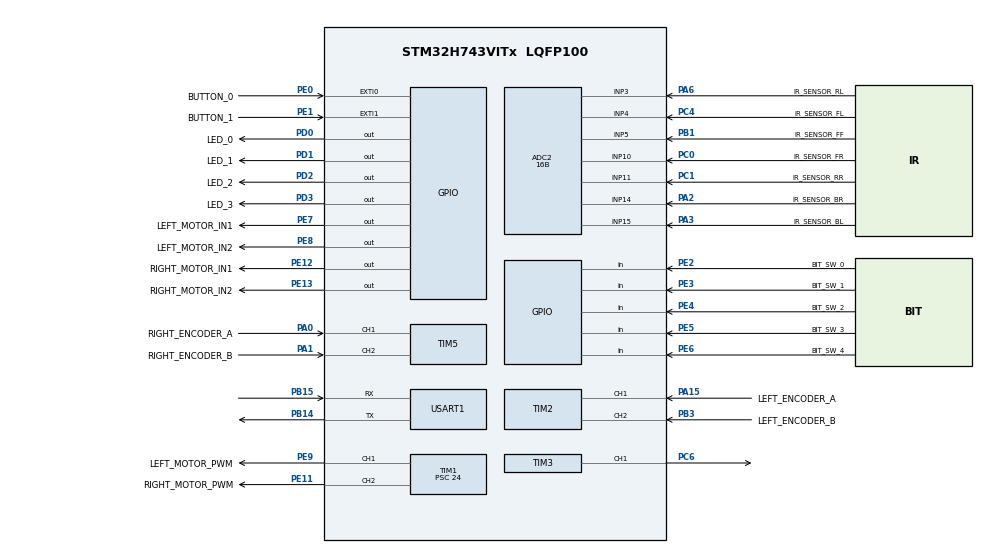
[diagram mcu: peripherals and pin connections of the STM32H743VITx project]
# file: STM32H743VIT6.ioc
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ADC2.Channel-1\#ChannelRegularConversion=ADC_CHANNEL_5
ADC2.Channel-2\#ChannelRegularConversion=ADC_CHANNEL_4
ADC2.Channel-3\#ChannelRegularConversion=ADC_CHANNEL_3
ADC2.Channel-4\#ChannelRegularConversion=ADC_CHANNEL_15
ADC2.Channel-5\#ChannelRegularConversion=ADC_CHANNEL_14
ADC2.Channel-6\#ChannelRegularConversion=ADC_CHANNEL_11
ADC2.Channel-8\#ChannelRegularConversion=ADC_CHANNEL_10
ADC2.ClockPrescaler=ADC_CLOCK_ASYNC_DIV256
ADC2.ContinuousConvMode=ENABLE
ADC2.DiscontinuousConvMode=DISABLE
ADC2.NbrOfConversion=7
ADC2.NbrOfConversionFlag=1
ADC2.OffsetNumber-1\#ChannelRegularConversion=ADC_OFFSET_NONE
ADC2.OffsetNumber-2\#ChannelRegularConversion=ADC_OFFSET_NONE
ADC2.OffsetNumber-3\#ChannelRegularConversion=ADC_OFFSET_NONE
ADC2.OffsetNumber-4\#ChannelRegularConversion=ADC_OFFSET_NONE
ADC2.OffsetNumber-5\#ChannelRegularConversion=ADC_OFFSET_NONE
ADC2.OffsetNumber-6\#ChannelRegularConversion=ADC_OFFSET_NONE
ADC2.OffsetNumber-8\#ChannelRegularConversion=ADC_OFFSET_NONE
ADC2.OffsetSignedSaturation-1\#ChannelRegularConversion=DISABLE
ADC2.OffsetSignedSaturation-2\#ChannelRegularConversion=DISABLE
ADC2.OffsetSignedSaturation-3\#ChannelRegularConversion=DISABLE
ADC2.OffsetSignedSaturation-4\#ChannelRegularConversion=DISABLE
ADC2.OffsetSignedSaturation-5\#ChannelRegularConversion=DISABLE
ADC2.OffsetSignedSaturation-6\#ChannelRegularConversion=DISABLE
ADC2.OffsetSignedSaturation-8\#ChannelRegularConversion=DISABLE
ADC2.OversamplingMode=DISABLE
ADC2.Rank-1\#ChannelRegularConversion=1
ADC2.Rank-2\#ChannelRegularConversion=2
ADC2.Rank-3\#ChannelRegularConversion=3
ADC2.Rank-4\#ChannelRegularConversion=4
ADC2.Rank-5\#ChannelRegularConversion=5
ADC2.Rank-6\#ChannelRegularConversion=6
ADC2.Rank-8\#ChannelRegularConversion=7
ADC2.Resolution=ADC_RESOLUTION_16B
ADC2.SamplingTime-1\#ChannelRegularConversion=ADC_SAMPLETIME_64CYCLES_5
ADC2.SamplingTime-2\#ChannelRegularConversion=ADC_SAMPLETIME_64CYCLES_5
ADC2.SamplingTime-3\#ChannelRegularConversion=ADC_SAMPLETIME_64CYCLES_5
ADC2.SamplingTime-4\#ChannelRegularConversion=ADC_SAMPLETIME_64CYCLES_5
ADC2.SamplingTime-5\#ChannelRegularConversion=ADC_SAMPLETIME_64CYCLES_5
ADC2.SamplingTime-6\#ChannelRegularConversion=ADC_SAMPLETIME_64CYCLES_5
ADC2.SamplingTime-8\#ChannelRegularConversion=ADC_SAMPLETIME_64CYCLES_5
CORTEX_M7.default_mode_Activation=1
Dma.Request0=USART1_RX
Dma.USART1_RX.0.Direction=DMA_PERIPH_TO_MEMORY
Dma.USART1_RX.0.EventEnable=DISABLE
Dma.USART1_RX.0.FIFOMode=DMA_FIFOMODE_DISABLE
Dma.USART1_RX.0.Instance=DMA1_Stream0
Dma.USART1_RX.0.MemDataAlignment=DMA_MDATAALIGN_BYTE
Dma.USART1_RX.0.MemInc=DMA_MINC_ENABLE
Dma.USART1_RX.0.Mode=DMA_NORMAL
Dma.USART1_RX.0.PeriphDataAlignment=DMA_PDATAALIGN_BYTE
Dma.USART1_RX.0.PeriphInc=DMA_PINC_DISABLE
Dma.USART1_RX.0.Polarity=HAL_DMAMUX_REQ_GEN_RISING
Dma.USART1_RX.0.Priority=DMA_PRIORITY_LOW
Dma.USART1_RX.0.RequestNumber=1
Dma.USART1_RX.0.SignalID=NONE
Dma.USART1_RX.0.SyncEnable=DISABLE
Dma.USART1_RX.0.SyncPolarity=HAL_DMAMUX_SYNC_NO_EVENT
Dma.USART1_RX.0.SyncRequestNumber=1
Dma.USART1_RX.0.SyncSignalID=NONE
Mcu.Family=STM32H7
Mcu.Name=STM32H743VITx
Mcu.Package=LQFP100
NVIC.ADC_IRQn=true\:0\:0\:false\:false\:true\:true\:true\:true
NVIC.DMA1_Stream0_IRQn=true\:1\:0\:true\:false\:true\:false\:true\:true
NVIC.PriorityGroup=NVIC_PRIORITYGROUP_4
NVIC.TIM7_IRQn=true\:2\:0\:true\:false\:true\:true\:true\:true
NVIC.USART1_IRQn=true\:1\:0\:true\:false\:true\:true\:true\:true
PA0.GPIO_Label=RIGHT_ENCODER_A
PA0.Signal=S_TIM5_CH1
PA1.GPIO_Label=RIGHT_ENCODER_B
PA1.Signal=S_TIM5_CH2
PA13\ (JTMS/SWDIO).Mode=Serial_Wire
PA13\ (JTMS/SWDIO).Signal=DEBUG_JTMS-SWDIO
PA14\ (JTCK/SWCLK).Mode=Serial_Wire
PA14\ (JTCK/SWCLK).Signal=DEBUG_JTCK-SWCLK
PA15\ (JTDI).GPIO_Label=LEFT_ENCODER_A
PA15\ (JTDI).Signal=S_TIM2_CH1_ETR
PA2.GPIO_Label=IR_SENSOR_BR
PA2.Signal=ADCx_INP14
PA3.GPIO_Label=IR_SENSOR_BL
PA3.Signal=ADCx_INP15
PA6.GPIO_Label=IR_SENSOR_RL
PA6.Signal=ADCx_INP3
PB1.GPIO_Label=IR_SENSOR_FF
PB1.Signal=ADCx_INP5
PB14.Mode=Asynchronous
PB14.Signal=USART1_TX
PB15.Mode=Asynchronous
PB15.Signal=USART1_RX
PB3\ (JTDO/TRACESWO).GPIO_Label=LEFT_ENCODER_B
PB3\ (JTDO/TRACESWO).Signal=S_TIM2_CH2
PC0.GPIO_Label=IR_SENSOR_FR
PC0.Signal=ADCx_INP10
PC1.GPIO_Label=IR_SENSOR_RR
PC1.Signal=ADCx_INP11
PC4.GPIO_Label=IR_SENSOR_FL
PC4.Signal=ADCx_INP4
PC6.Signal=S_TIM3_CH1
PD0.GPIO_Label=LED_0
PD0.Signal=GPIO_Output
PD1.GPIO_Label=LED_1
PD1.Signal=GPIO_Output
PD2.GPIO_Label=LED_2
PD2.Signal=GPIO_Output
PD3.GPIO_Label=LED_3
PD3.Signal=GPIO_Output
PE0.GPIO_Label=BUTTON_0
PE0.Signal=GPXTI0
PE1.GPIO_Label=BUTTON_1
PE1.Signal=GPXTI1
PE11.GPIO_Label=RIGHT_MOTOR_PWM
PE11.Signal=S_TIM1_CH2
PE12.GPIO_Label=RIGHT_MOTOR_IN1
PE12.Signal=GPIO_Output
PE13.GPIO_Label=RIGHT_MOTOR_IN2
PE13.Signal=GPIO_Output
PE2.GPIO_Label=BIT_SW_0
PE2.GPIO_PuPd=GPIO_PULLDOWN
PE2.Signal=GPIO_Input
PE3.GPIO_Label=BIT_SW_1
PE3.GPIO_PuPd=GPIO_PULLDOWN
PE3.Signal=GPIO_Input
PE4.GPIO_Label=BIT_SW_2
PE4.GPIO_PuPd=GPIO_PULLDOWN
PE4.Signal=GPIO_Input
PE5.GPIO_Label=BIT_SW_3
PE5.GPIO_PuPd=GPIO_PULLDOWN
PE5.Signal=GPIO_Input
PE6.GPIO_Label=BIT_SW_4
PE6.GPIO_PuPd=GPIO_PULLDOWN
PE6.Signal=GPIO_Input
PE7.GPIO_Label=LEFT_MOTOR_IN1
PE7.Signal=GPIO_Output
PE8.GPIO_Label=LEFT_MOTOR_IN2
PE8.Signal=GPIO_Output
PE9.GPIO_Label=LEFT_MOTOR_PWM
PE9.Signal=S_TIM1_CH1
PH0-OSC_IN\ (PH0).Mode=HSE-External-Oscillator
PH0-OSC_IN\ (PH0).Signal=RCC_OSC_IN
PH1-OSC_OUT\ (PH1).Mode=HSE-External-Oscillator
PH1-OSC_OUT\ (PH1).Signal=RCC_OSC_OUT
ProjectManager.HeapSize=0x200
ProjectManager.StackSize=0x400
ProjectManager.TargetToolchain=STM32CubeIDE
RCC.ADCFreq_Value=96750000
RCC.APB1Freq_Value=120000000
RCC.APB2Freq_Value=120000000
RCC.APB3Freq_Value=120000000
RCC.APB4Freq_Value=120000000
RCC.CortexFreq_Value=480000000
RCC.D1PPRE=RCC_APB3_DIV2
RCC.D2PPRE1=RCC_APB1_DIV2
RCC.D2PPRE2=RCC_APB2_DIV2
RCC.D3PPRE=RCC_APB4_DIV2
RCC.DIVM1=3
RCC.DIVN1=60
RCC.HCLKFreq_Value=240000000
RCC.HPRE=RCC_HCLK_DIV2
RCC.HSE_VALUE=48000000
RCC.PLLFRACN=0
RCC.PLLSourceVirtual=RCC_PLLSOURCE_HSE
RCC.SYSCLKFreq_VALUE=480000000
RCC.SYSCLKSource=RCC_SYSCLKSOURCE_PLLCLK
RCC.USBFreq_Value=480000000
SH.ADCx_INP10.0=ADC2_INP10,IN10-Single-Ended
SH.ADCx_INP11.0=ADC2_INP11,IN11-Single-Ended
SH.ADCx_INP14.0=ADC2_INP14,IN14-Single-Ended
SH.ADCx_INP15.0=ADC2_INP15,IN15-Single-Ended
SH.ADCx_INP3.0=ADC2_INP3,IN3-Single-Ended
SH.ADCx_INP4.0=ADC2_INP4,IN4-Single-Ended
SH.ADCx_INP5.0=ADC2_INP5,IN5-Single-Ended
SH.S_TIM1_CH1.0=TIM1_CH1,PWM Generation1 CH1
SH.S_TIM1_CH2.0=TIM1_CH2,PWM Generation2 CH2
SH.S_TIM2_CH1_ETR.0=TIM2_CH1,Encoder_Interface
SH.S_TIM2_CH2.0=TIM2_CH2,Encoder_Interface
SH.S_TIM3_CH1.0=TIM3_CH1,PWM Generation1 CH1
SH.S_TIM5_CH1.0=TIM5_CH1,Encoder_Interface
SH.S_TIM5_CH2.0=TIM5_CH2,Encoder_Interface
TIM1.Channel-PWM\ Generation1\ CH1=TIM_CHANNEL_1
TIM1.Channel-PWM\ Generation2\ CH2=TIM_CHANNEL_2
TIM1.Period=999
TIM1.Prescaler=24
TIM2.ClockDivision=TIM_CLOCKDIVISION_DIV1
TIM2.IC1Polarity=TIM_ICPOLARITY_RISING
TIM2.IC2Polarity=TIM_ICPOLARITY_RISING
TIM3.Channel-PWM\ Generation1\ CH1=TIM_CHANNEL_1
TIM3.OCMode_PWM-PWM\ Generation1\ CH1=TIM_OCMODE_PWM2
TIM3.Period=65535
TIM3.Prescaler=4000
TIM5.ClockDivision=TIM_CLOCKDIVISION_DIV1
TIM5.EncoderMode=TIM_ENCODERMODE_TI12
TIM5.IC1Polarity=TIM_ICPOLARITY_RISING
TIM5.IC2Polarity=TIM_ICPOLARITY_FALLING
TIM7.Period=199
TIM7.Prescaler=24000
USART1.OverrunDisableParam=ADVFEATURE_OVERRUN_ENABLE
USART1.VirtualMode-Asynchronous=VM_ASYNC
VP_MEMORYMAP_VS_MEMORYMAP.Mode=CurAppReg
VP_TIM7_VS_ClockSourceINT.Mode=Enable_Timer
board=custom

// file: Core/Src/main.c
/* USER CODE BEGIN Header */
/**
  ******************************************************************************
  * @file           : main.c
  * @brief          : Main program body
  ******************************************************************************
  * @attention
  *
  * Copyright (c) 2025 STMicroelectronics.
  * All rights reserved.
  *
  * This software is licensed under terms that can be found in the LICENSE file
  * in the root directory of this software component.
  * If no LICENSE file comes with this software, it is provided AS-IS.
  *
  ******************************************************************************
  */
/* USER CODE END Header */
#include "main.h"

/* USER CODE BEGIN Includes */
#include "AML_GlobalVariable.h"
#include "AML_IMU.h"
#include "AML_IRSensor.h"

#include <string.h>

#include "AML_LedDebug.h"
#include "AML_Buzzer.h"
#include "AML_Switch.h"
#include "AML_MotorControl.h"
#include "AML_Encoder.h"

#include "solver.h"
/* USER CODE END Includes */

ADC_HandleTypeDef hadc2;

TIM_HandleTypeDef htim1;
TIM_HandleTypeDef htim2;
TIM_HandleTypeDef htim3;
TIM_HandleTypeDef htim5;
TIM_HandleTypeDef htim7;

UART_HandleTypeDef huart1;
DMA_HandleTypeDef hdma_usart1_rx;

void SystemClock_Config(void);
static void MPU_Config(void);
static void MX_GPIO_Init(void);
static void MX_DMA_Init(void);
static void MX_TIM2_Init(void);
static void MX_ADC2_Init(void);
static void MX_TIM1_Init(void);
static void MX_TIM5_Init(void);
static void MX_USART1_UART_Init(void);
static void MX_TIM3_Init(void);
static void MX_TIM7_Init(void);

int main(void)
{

  /* MPU Configuration--------------------------------------------------------*/
  MPU_Config();

  /* MCU Configuration--------------------------------------------------------*/

  /* Reset of all peripherals, Initializes the Flash interface and the Systick. */
  HAL_Init();

  /* Configure the system clock */
  SystemClock_Config();

  /* Initialize all configured peripherals */
  MX_GPIO_Init();
  MX_DMA_Init();
  MX_TIM2_Init();
  MX_ADC2_Init();
  MX_TIM1_Init();
  MX_TIM5_Init();
  MX_USART1_UART_Init();
  MX_TIM3_Init();
  MX_TIM7_Init();

  /* Infinite loop */
  while (1)
  {

  }
}

void SystemClock_Config(void)
{
  RCC_OscInitTypeDef RCC_OscInitStruct = {0};
  RCC_ClkInitTypeDef RCC_ClkInitStruct = {0};

  /** Supply configuration update enable
  */
  HAL_PWREx_ConfigSupply(PWR_LDO_SUPPLY);

  /** Configure the main internal regulator output voltage
  */
  __HAL_PWR_VOLTAGESCALING_CONFIG(PWR_REGULATOR_VOLTAGE_SCALE0);

  while(!__HAL_PWR_GET_FLAG(PWR_FLAG_VOSRDY)) {}

  /** Initializes the RCC Oscillators according to the specified parameters
  * in the RCC_OscInitTypeDef structure.
  */
  RCC_OscInitStruct.OscillatorType = RCC_OSCILLATORTYPE_HSE;
  RCC_OscInitStruct.HSEState = RCC_HSE_ON;
  RCC_OscInitStruct.PLL.PLLState = RCC_PLL_ON;
  RCC_OscInitStruct.PLL.PLLSource = RCC_PLLSOURCE_HSE;
  RCC_OscInitStruct.PLL.PLLM = 3;
  RCC_OscInitStruct.PLL.PLLN = 60;
  RCC_OscInitStruct.PLL.PLLP = 2;
  RCC_OscInitStruct.PLL.PLLQ = 2;
  RCC_OscInitStruct.PLL.PLLR = 2;
  RCC_OscInitStruct.PLL.PLLRGE = RCC_PLL1VCIRANGE_3;
  RCC_OscInitStruct.PLL.PLLVCOSEL = RCC_PLL1VCOWIDE;
  RCC_OscInitStruct.PLL.PLLFRACN = 0;
  if (HAL_RCC_OscConfig(&RCC_OscInitStruct) != HAL_OK)
  {
    Error_Handler();
  }

  /** Initializes the CPU, AHB and APB buses clocks
  */
  RCC_ClkInitStruct.ClockType = RCC_CLOCKTYPE_HCLK|RCC_CLOCKTYPE_SYSCLK
                              |RCC_CLOCKTYPE_PCLK1|RCC_CLOCKTYPE_PCLK2
                              |RCC_CLOCKTYPE_D3PCLK1|RCC_CLOCKTYPE_D1PCLK1;
  RCC_ClkInitStruct.SYSCLKSource = RCC_SYSCLKSOURCE_PLLCLK;
  RCC_ClkInitStruct.SYSCLKDivider = RCC_SYSCLK_DIV1;
  RCC_ClkInitStruct.AHBCLKDivider = RCC_HCLK_DIV2;
  RCC_ClkInitStruct.APB3CLKDivider = RCC_APB3_DIV2;
  RCC_ClkInitStruct.APB1CLKDivider = RCC_APB1_DIV2;
  RCC_ClkInitStruct.APB2CLKDivider = RCC_APB2_DIV2;
  RCC_ClkInitStruct.APB4CLKDivider = RCC_APB4_DIV2;

  if (HAL_RCC_ClockConfig(&RCC_ClkInitStruct, FLASH_LATENCY_4) != HAL_OK)
  {
    Error_Handler();
  }
}

static void MX_ADC2_Init(void)
{

  ADC_ChannelConfTypeDef sConfig = {0};

  /** Common config
  */
  hadc2.Instance = ADC2;
  hadc2.Init.ClockPrescaler = ADC_CLOCK_ASYNC_DIV256;
  hadc2.Init.Resolution = ADC_RESOLUTION_16B;
  hadc2.Init.ScanConvMode = ADC_SCAN_ENABLE;
  hadc2.Init.EOCSelection = ADC_EOC_SINGLE_CONV;
  hadc2.Init.LowPowerAutoWait = DISABLE;
  hadc2.Init.ContinuousConvMode = ENABLE;
  hadc2.Init.NbrOfConversion = 7;
  hadc2.Init.DiscontinuousConvMode = DISABLE;
  hadc2.Init.ExternalTrigConv = ADC_SOFTWARE_START;
  hadc2.Init.ExternalTrigConvEdge = ADC_EXTERNALTRIGCONVEDGE_NONE;
  hadc2.Init.ConversionDataManagement = ADC_CONVERSIONDATA_DR;
  hadc2.Init.Overrun = ADC_OVR_DATA_PRESERVED;
  hadc2.Init.LeftBitShift = ADC_LEFTBITSHIFT_NONE;
  hadc2.Init.OversamplingMode = DISABLE;
  hadc2.Init.Oversampling.Ratio = 1;
  if (HAL_ADC_Init(&hadc2) != HAL_OK)
  {
    Error_Handler();
  }

  /** Configure Regular Channel
  */
  sConfig.Channel = ADC_CHANNEL_5;
  sConfig.Rank = ADC_REGULAR_RANK_1;
  sConfig.SamplingTime = ADC_SAMPLETIME_64CYCLES_5;
  sConfig.SingleDiff = ADC_SINGLE_ENDED;
  sConfig.OffsetNumber = ADC_OFFSET_NONE;
  sConfig.Offset = 0;
  sConfig.OffsetSignedSaturation = DISABLE;
  if (HAL_ADC_ConfigChannel(&hadc2, &sConfig) != HAL_OK)
  {
    Error_Handler();
  }

  /** Configure Regular Channel
  */
  sConfig.Channel = ADC_CHANNEL_4;
  sConfig.Rank = ADC_REGULAR_RANK_2;
  if (HAL_ADC_ConfigChannel(&hadc2, &sConfig) != HAL_OK)
  {
    Error_Handler();
  }

  /** Configure Regular Channel
  */
  sConfig.Channel = ADC_CHANNEL_3;
  sConfig.Rank = ADC_REGULAR_RANK_3;
  if (HAL_ADC_ConfigChannel(&hadc2, &sConfig) != HAL_OK)
  {
    Error_Handler();
  }

  /** Configure Regular Channel
  */
  sConfig.Channel = ADC_CHANNEL_15;
  sConfig.Rank = ADC_REGULAR_RANK_4;
  if (HAL_ADC_ConfigChannel(&hadc2, &sConfig) != HAL_OK)
  {
    Error_Handler();
  }

  /** Configure Regular Channel
  */
  sConfig.Channel = ADC_CHANNEL_14;
  sConfig.Rank = ADC_REGULAR_RANK_5;
  if (HAL_ADC_ConfigChannel(&hadc2, &sConfig) != HAL_OK)
  {
    Error_Handler();
  }

  /** Configure Regular Channel
  */
  sConfig.Channel = ADC_CHANNEL_11;
  sConfig.Rank = ADC_REGULAR_RANK_6;
  if (HAL_ADC_ConfigChannel(&hadc2, &sConfig) != HAL_OK)
  {
    Error_Handler();
  }

  /** Configure Regular Channel
  */
  sConfig.Channel = ADC_CHANNEL_10;
  sConfig.Rank = ADC_REGULAR_RANK_7;
  if (HAL_ADC_ConfigChannel(&hadc2, &sConfig) != HAL_OK)
  {
    Error_Handler();
  }

}

static void MX_TIM1_Init(void)
{

  TIM_MasterConfigTypeDef sMasterConfig = {0};
  TIM_OC_InitTypeDef sConfigOC = {0};
  TIM_BreakDeadTimeConfigTypeDef sBreakDeadTimeConfig = {0};

  htim1.Instance = TIM1;
  htim1.Init.Prescaler = 24;
  htim1.Init.CounterMode = TIM_COUNTERMODE_UP;
  htim1.Init.Period = 999;
  htim1.Init.ClockDivision = TIM_CLOCKDIVISION_DIV1;
  htim1.Init.RepetitionCounter = 0;
  htim1.Init.AutoReloadPreload = TIM_AUTORELOAD_PRELOAD_DISABLE;
  if (HAL_TIM_PWM_Init(&htim1) != HAL_OK)
  {
    Error_Handler();
  }
  sMasterConfig.MasterOutputTrigger = TIM_TRGO_RESET;
  sMasterConfig.MasterOutputTrigger2 = TIM_TRGO2_RESET;
  sMasterConfig.MasterSlaveMode = TIM_MASTERSLAVEMODE_DISABLE;
  if (HAL_TIMEx_MasterConfigSynchronization(&htim1, &sMasterConfig) != HAL_OK)
  {
    Error_Handler();
  }
  sConfigOC.OCMode = TIM_OCMODE_PWM1;
  sConfigOC.Pulse = 0;
  sConfigOC.OCPolarity = TIM_OCPOLARITY_HIGH;
  sConfigOC.OCNPolarity = TIM_OCNPOLARITY_HIGH;
  sConfigOC.OCFastMode = TIM_OCFAST_DISABLE;
  sConfigOC.OCIdleState = TIM_OCIDLESTATE_RESET;
  sConfigOC.OCNIdleState = TIM_OCNIDLESTATE_RESET;
  if (HAL_TIM_PWM_ConfigChannel(&htim1, &sConfigOC, TIM_CHANNEL_1) != HAL_OK)
  {
    Error_Handler();
  }
  if (HAL_TIM_PWM_ConfigChannel(&htim1, &sConfigOC, TIM_CHANNEL_2) != HAL_OK)
  {
    Error_Handler();
  }
  sBreakDeadTimeConfig.OffStateRunMode = TIM_OSSR_DISABLE;
  sBreakDeadTimeConfig.OffStateIDLEMode = TIM_OSSI_DISABLE;
  sBreakDeadTimeConfig.LockLevel = TIM_LOCKLEVEL_OFF;
  sBreakDeadTimeConfig.DeadTime = 0;
  sBreakDeadTimeConfig.BreakState = TIM_BREAK_DISABLE;
  sBreakDeadTimeConfig.BreakPolarity = TIM_BREAKPOLARITY_HIGH;
  sBreakDeadTimeConfig.BreakFilter = 0;
  sBreakDeadTimeConfig.Break2State = TIM_BREAK2_DISABLE;
  sBreakDeadTimeConfig.Break2Polarity = TIM_BREAK2POLARITY_HIGH;
  sBreakDeadTimeConfig.Break2Filter = 0;
  sBreakDeadTimeConfig.AutomaticOutput = TIM_AUTOMATICOUTPUT_DISABLE;
  if (HAL_TIMEx_ConfigBreakDeadTime(&htim1, &sBreakDeadTimeConfig) != HAL_OK)
  {
    Error_Handler();
  }
  HAL_TIM_MspPostInit(&htim1);

}

static void MX_TIM2_Init(void)
{

  TIM_Encoder_InitTypeDef sConfig = {0};
  TIM_MasterConfigTypeDef sMasterConfig = {0};

  htim2.Instance = TIM2;
  htim2.Init.Prescaler = 0;
  htim2.Init.CounterMode = TIM_COUNTERMODE_UP;
  htim2.Init.Period = 4294967295;
  htim2.Init.ClockDivision = TIM_CLOCKDIVISION_DIV1;
  htim2.Init.AutoReloadPreload = TIM_AUTORELOAD_PRELOAD_DISABLE;
  sConfig.EncoderMode = TIM_ENCODERMODE_TI1;
  sConfig.IC1Polarity = TIM_ICPOLARITY_RISING;
  sConfig.IC1Selection = TIM_ICSELECTION_DIRECTTI;
  sConfig.IC1Prescaler = TIM_ICPSC_DIV1;
  sConfig.IC1Filter = 0;
  sConfig.IC2Polarity = TIM_ICPOLARITY_RISING;
  sConfig.IC2Selection = TIM_ICSELECTION_DIRECTTI;
  sConfig.IC2Prescaler = TIM_ICPSC_DIV1;
  sConfig.IC2Filter = 0;
  if (HAL_TIM_Encoder_Init(&htim2, &sConfig) != HAL_OK)
  {
    Error_Handler();
  }
  sMasterConfig.MasterOutputTrigger = TIM_TRGO_RESET;
  sMasterConfig.MasterSlaveMode = TIM_MASTERSLAVEMODE_DISABLE;
  if (HAL_TIMEx_MasterConfigSynchronization(&htim2, &sMasterConfig) != HAL_OK)
  {
    Error_Handler();
  }

}

static void MX_TIM3_Init(void)
{

  TIM_MasterConfigTypeDef sMasterConfig = {0};
  TIM_OC_InitTypeDef sConfigOC = {0};

  htim3.Instance = TIM3;
  htim3.Init.Prescaler = 4000;
  htim3.Init.CounterMode = TIM_COUNTERMODE_UP;
  htim3.Init.Period = 65535;
  htim3.Init.ClockDivision = TIM_CLOCKDIVISION_DIV1;
  htim3.Init.AutoReloadPreload = TIM_AUTORELOAD_PRELOAD_DISABLE;
  if (HAL_TIM_PWM_Init(&htim3) != HAL_OK)
  {
    Error_Handler();
  }
  sMasterConfig.MasterOutputTrigger = TIM_TRGO_RESET;
  sMasterConfig.MasterSlaveMode = TIM_MASTERSLAVEMODE_DISABLE;
  if (HAL_TIMEx_MasterConfigSynchronization(&htim3, &sMasterConfig) != HAL_OK)
  {
    Error_Handler();
  }
  sConfigOC.OCMode = TIM_OCMODE_PWM2;
  sConfigOC.Pulse = 0;
  sConfigOC.OCPolarity = TIM_OCPOLARITY_HIGH;
  sConfigOC.OCFastMode = TIM_OCFAST_DISABLE;
  if (HAL_TIM_PWM_ConfigChannel(&htim3, &sConfigOC, TIM_CHANNEL_1) != HAL_OK)
  {
    Error_Handler();
  }
  HAL_TIM_MspPostInit(&htim3);

}

static void MX_TIM5_Init(void)
{

  TIM_Encoder_InitTypeDef sConfig = {0};
  TIM_MasterConfigTypeDef sMasterConfig = {0};

  htim5.Instance = TIM5;
  htim5.Init.Prescaler = 0;
  htim5.Init.CounterMode = TIM_COUNTERMODE_UP;
  htim5.Init.Period = 4294967295;
  htim5.Init.ClockDivision = TIM_CLOCKDIVISION_DIV1;
  htim5.Init.AutoReloadPreload = TIM_AUTORELOAD_PRELOAD_DISABLE;
  sConfig.EncoderMode = TIM_ENCODERMODE_TI12;
  sConfig.IC1Polarity = TIM_ICPOLARITY_RISING;
  sConfig.IC1Selection = TIM_ICSELECTION_DIRECTTI;
  sConfig.IC1Prescaler = TIM_ICPSC_DIV1;
  sConfig.IC1Filter = 0;
  sConfig.IC2Polarity = TIM_ICPOLARITY_FALLING;
  sConfig.IC2Selection = TIM_ICSELECTION_DIRECTTI;
  sConfig.IC2Prescaler = TIM_ICPSC_DIV1;
  sConfig.IC2Filter = 0;
  if (HAL_TIM_Encoder_Init(&htim5, &sConfig) != HAL_OK)
  {
    Error_Handler();
  }
  sMasterConfig.MasterOutputTrigger = TIM_TRGO_RESET;
  sMasterConfig.MasterSlaveMode = TIM_MASTERSLAVEMODE_DISABLE;
  if (HAL_TIMEx_MasterConfigSynchronization(&htim5, &sMasterConfig) != HAL_OK)
  {
    Error_Handler();
  }

}

static void MX_TIM7_Init(void)
{

  TIM_MasterConfigTypeDef sMasterConfig = {0};

  htim7.Instance = TIM7;
  htim7.Init.Prescaler = 24000;
  htim7.Init.CounterMode = TIM_COUNTERMODE_UP;
  htim7.Init.Period = 199;
  htim7.Init.AutoReloadPreload = TIM_AUTORELOAD_PRELOAD_DISABLE;
  if (HAL_TIM_Base_Init(&htim7) != HAL_OK)
  {
    Error_Handler();
  }
  sMasterConfig.MasterOutputTrigger = TIM_TRGO_RESET;
  sMasterConfig.MasterSlaveMode = TIM_MASTERSLAVEMODE_DISABLE;
  if (HAL_TIMEx_MasterConfigSynchronization(&htim7, &sMasterConfig) != HAL_OK)
  {
    Error_Handler();
  }

}

static void MX_USART1_UART_Init(void)
{

  huart1.Instance = USART1;
  huart1.Init.BaudRate = 115200;
  huart1.Init.WordLength = UART_WORDLENGTH_8B;
  huart1.Init.StopBits = UART_STOPBITS_1;
  huart1.Init.Parity = UART_PARITY_NONE;
  huart1.Init.Mode = UART_MODE_TX_RX;
  huart1.Init.HwFlowCtl = UART_HWCONTROL_NONE;
  huart1.Init.OverSampling = UART_OVERSAMPLING_16;
  huart1.Init.OneBitSampling = UART_ONE_BIT_SAMPLE_DISABLE;
  huart1.Init.ClockPrescaler = UART_PRESCALER_DIV1;
  huart1.AdvancedInit.AdvFeatureInit = UART_ADVFEATURE_NO_INIT;
  if (HAL_UART_Init(&huart1) != HAL_OK)
  {
    Error_Handler();
  }
  if (HAL_UARTEx_SetTxFifoThreshold(&huart1, UART_TXFIFO_THRESHOLD_1_8) != HAL_OK)
  {
    Error_Handler();
  }
  if (HAL_UARTEx_SetRxFifoThreshold(&huart1, UART_RXFIFO_THRESHOLD_1_8) != HAL_OK)
  {
    Error_Handler();
  }
  if (HAL_UARTEx_DisableFifoMode(&huart1) != HAL_OK)
  {
    Error_Handler();
  }

}

static void MX_DMA_Init(void)
{

  /* DMA controller clock enable */
  __HAL_RCC_DMA1_CLK_ENABLE();

  /* DMA interrupt init */
  /* DMA1_Stream0_IRQn interrupt configuration */
  HAL_NVIC_SetPriority(DMA1_Stream0_IRQn, 1, 0);
  HAL_NVIC_EnableIRQ(DMA1_Stream0_IRQn);

}

static void MX_GPIO_Init(void)
{
  GPIO_InitTypeDef GPIO_InitStruct = {0};

  /* GPIO Ports Clock Enable */
  __HAL_RCC_GPIOE_CLK_ENABLE();
  __HAL_RCC_GPIOH_CLK_ENABLE();
  __HAL_RCC_GPIOC_CLK_ENABLE();
  __HAL_RCC_GPIOA_CLK_ENABLE();
  __HAL_RCC_GPIOB_CLK_ENABLE();
  __HAL_RCC_GPIOD_CLK_ENABLE();

  /*Configure GPIO pin Output Level */
  HAL_GPIO_WritePin(GPIOE, LEFT_MOTOR_IN1_Pin|LEFT_MOTOR_IN2_Pin|RIGHT_MOTOR_IN1_Pin|RIGHT_MOTOR_IN2_Pin, GPIO_PIN_RESET);

  /*Configure GPIO pin Output Level */
  HAL_GPIO_WritePin(GPIOD, LED_0_Pin|LED_1_Pin|LED_2_Pin|LED_3_Pin, GPIO_PIN_RESET);

  /*Configure GPIO pins : BIT_SW_0_Pin BIT_SW_1_Pin BIT_SW_2_Pin BIT_SW_3_Pin
                           BIT_SW_4_Pin */
  GPIO_InitStruct.Pin = BIT_SW_0_Pin|BIT_SW_1_Pin|BIT_SW_2_Pin|BIT_SW_3_Pin
                          |BIT_SW_4_Pin;
  GPIO_InitStruct.Mode = GPIO_MODE_INPUT;
  GPIO_InitStruct.Pull = GPIO_PULLDOWN;
  HAL_GPIO_Init(GPIOE, &GPIO_InitStruct);

  /*Configure GPIO pins : LEFT_MOTOR_IN1_Pin LEFT_MOTOR_IN2_Pin RIGHT_MOTOR_IN1_Pin RIGHT_MOTOR_IN2_Pin */
  GPIO_InitStruct.Pin = LEFT_MOTOR_IN1_Pin|LEFT_MOTOR_IN2_Pin|RIGHT_MOTOR_IN1_Pin|RIGHT_MOTOR_IN2_Pin;
  GPIO_InitStruct.Mode = GPIO_MODE_OUTPUT_PP;
  GPIO_InitStruct.Pull = GPIO_NOPULL;
  GPIO_InitStruct.Speed = GPIO_SPEED_FREQ_LOW;
  HAL_GPIO_Init(GPIOE, &GPIO_InitStruct);

  /*Configure GPIO pins : LED_0_Pin LED_1_Pin LED_2_Pin LED_3_Pin */
  GPIO_InitStruct.Pin = LED_0_Pin|LED_1_Pin|LED_2_Pin|LED_3_Pin;
  GPIO_InitStruct.Mode = GPIO_MODE_OUTPUT_PP;
  GPIO_InitStruct.Pull = GPIO_NOPULL;
  GPIO_InitStruct.Speed = GPIO_SPEED_FREQ_LOW;
  HAL_GPIO_Init(GPIOD, &GPIO_InitStruct);

  /*Configure GPIO pins : BUTTON_0_Pin BUTTON_1_Pin */
  GPIO_InitStruct.Pin = BUTTON_0_Pin|BUTTON_1_Pin;
  GPIO_InitStruct.Mode = GPIO_MODE_IT_RISING;
  GPIO_InitStruct.Pull = GPIO_NOPULL;
  HAL_GPIO_Init(GPIOE, &GPIO_InitStruct);

}

 /* MPU Configuration */

void MPU_Config(void)
{
  MPU_Region_InitTypeDef MPU_InitStruct = {0};

  /* Disables the MPU */
  HAL_MPU_Disable();

  /** Initializes and configures the Region and the memory to be protected
  */
  MPU_InitStruct.Enable = MPU_REGION_ENABLE;
  MPU_InitStruct.Number = MPU_REGION_NUMBER0;
  MPU_InitStruct.BaseAddress = 0x0;
  MPU_InitStruct.Size = MPU_REGION_SIZE_4GB;
  MPU_InitStruct.SubRegionDisable = 0x87;
  MPU_InitStruct.TypeExtField = MPU_TEX_LEVEL0;
  MPU_InitStruct.AccessPermission = MPU_REGION_NO_ACCESS;
  MPU_InitStruct.DisableExec = MPU_INSTRUCTION_ACCESS_DISABLE;
  MPU_InitStruct.IsShareable = MPU_ACCESS_SHAREABLE;
  MPU_InitStruct.IsCacheable = MPU_ACCESS_NOT_CACHEABLE;
  MPU_InitStruct.IsBufferable = MPU_ACCESS_NOT_BUFFERABLE;

  HAL_MPU_ConfigRegion(&MPU_InitStruct);
  /* Enables the MPU */
  HAL_MPU_Enable(MPU_PRIVILEGED_DEFAULT);

}

void Error_Handler(void)
{
  __disable_irq();
  while (1)
  {
  }
}
